# STM32F3x4 register map
File version: 1.8
CPU: CM4 r1p0, little endian, MPU, FPU, 4 interrupt priority bits
Registers are 32-bit, read-write, reset 0x0 unless marked. A register's access mark holds for its fields unless they carry their own. Offsets are from the block's base; [hi:lo] are bit positions; {n}, {i} and the like mark numbered series; 'fields as' and 'values as' point back to an identical list.

## TIM2 — General purpose timer
Base 0x40000000
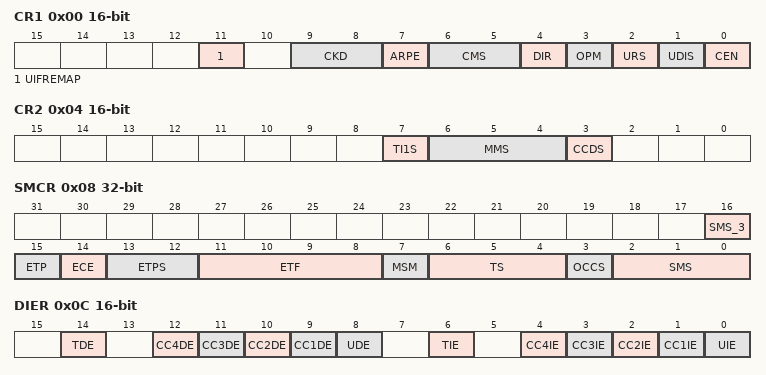
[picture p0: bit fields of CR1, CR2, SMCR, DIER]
0x00 CR1 16-bit — control register 1
  [11] UIFREMAP — UIF status bit remapping
  [9:8] CKD — Clock division
    0=Div1 (t_DTS = t_CK_INT); 1=Div2 (t_DTS = 2 × t_CK_INT); 2=Div4 (t_DTS = 4 × t_CK_INT)
  [7] ARPE — Auto-reload preload enable
    0=Disabled (TIMx_APRR register is not buffered); 1=Enabled (TIMx_APRR register is buffered)
  [6:5] CMS — Center-aligned mode selection
    0=EdgeAligned (The counter counts up or down depending on the direction bit); 1=CenterAligned1 (The counter counts up and down alternatively. Output compare interrupt flags are set only when the counter is counting down.); 2=CenterAligned2 (The counter counts up and down alternatively. Output compare interrupt flags are set only when the counter is counting up.); 3=CenterAligned3 (The counter counts up and down alternatively. Output compare interrupt flags are set both when the counter is counting up or down.)
  [4] DIR — Direction
    0=Up (Counter used as upcounter); 1=Down (Counter used as downcounter)
  [3] OPM — One-pulse mode
    0=Disabled (Counter is not stopped at update event); 1=Enabled (Counter stops counting at the next update event (clearing the CEN bit))
  [2] URS — Update request source
    0=AnyEvent (Any of counter overflow/underflow, setting UG, or update through slave mode, generates an update interrupt or DMA request); 1=CounterOnly (Only counter overflow/underflow generates an update interrupt or DMA request)
  [1] UDIS — Update disable
    0=Enabled (Update event enabled); 1=Disabled (Update event disabled)
  [0] CEN — Counter enable
    0=Disabled (Counter disabled); 1=Enabled (Counter enabled)
0x04 CR2 16-bit — control register 2
  [7] TI1S — TI1 selection
    0=Normal (The TIMx_CH1 pin is connected to TI1 input); 1=XOR (The TIMx_CH1, CH2, CH3 pins are connected to TI1 input)
  [6:4] MMS — Master mode selection
    0=Reset (The UG bit from the TIMx_EGR register is used as trigger output); 1=Enable (The counter enable signal, CNT_EN, is used as trigger output); 2=Update (The update event is selected as trigger output); 3=ComparePulse (The trigger output send a positive pulse when the CC1IF flag it to be set, as soon as a capture or a compare match occurred); {v}=CompareOC{v-3} (OC{v-3}REF signal is used as trigger output) (v=4..7)
  [3] CCDS — Capture/compare DMA selection
    0=OnCompare (CCx DMA request sent when CCx event occurs); 1=OnUpdate (CCx DMA request sent when update event occurs)
0x08 SMCR — slave mode control register
  [16] SMS_3 — Slave mode selection bit3
  [15] ETP — External trigger polarity
    0=NotInverted (ETR is noninverted, active at high level or rising edge); 1=Inverted (ETR is inverted, active at low level or falling edge)
  [14] ECE — External clock enable
    0=Disabled (External clock mode 2 disabled); 1=Enabled (External clock mode 2 enabled. The counter is clocked by any active edge on the ETRF signal.)
  [13:12] ETPS — External trigger prescaler
    0=Div1 (Prescaler OFF); 1=Div2 (ETRP frequency divided by 2); 2=Div4 (ETRP frequency divided by 4); 3=Div8 (ETRP frequency divided by 8)
  [11:8] ETF — External trigger filter
    0=No filter, sampling is done at fDTS; 1=FCK_INT_N2 (fSAMPLING=fCK_INT, N=2); 2=FCK_INT_N4 (fSAMPLING=fCK_INT, N=4); 3=FCK_INT_N8 (fSAMPLING=fCK_INT, N=8); 4=FDTS_Div2_N6 (fSAMPLING=fDTS/2, N=6); 5=FDTS_Div2_N8 (fSAMPLING=fDTS/2, N=8); 6=FDTS_Div4_N6 (fSAMPLING=fDTS/4, N=6); 7=FDTS_Div4_N8 (fSAMPLING=fDTS/4, N=8); 8=FDTS_Div8_N6 (fSAMPLING=fDTS/8, N=6); 9=FDTS_Div8_N8 (fSAMPLING=fDTS/8, N=8); 10=FDTS_Div16_N5 (fSAMPLING=fDTS/16, N=5); 11=FDTS_Div16_N6 (fSAMPLING=fDTS/16, N=6); 12=FDTS_Div16_N8 (fSAMPLING=fDTS/16, N=8); 13=FDTS_Div32_N5 (fSAMPLING=fDTS/32, N=5); 14=FDTS_Div32_N6 (fSAMPLING=fDTS/32, N=6); 15=FDTS_Div32_N8 (fSAMPLING=fDTS/32, N=8)
  [7] MSM — Master/Slave mode
    0=NoSync (No action); 1=Sync (The effect of an event on the trigger input (TRGI) is delayed to allow a perfect synchronization between the current timer and its slaves (through TRGO). It is useful if we want to synchronize several timers on a single external event.)
  [6:4] TS — Trigger selection
    0=ITR0 (Internal Trigger 0 (ITR0)); 1=ITR1 (Internal Trigger 1 (ITR1)); 2=ITR2 (Internal Trigger 2 (ITR2)); 4=TI1F_ED (TI1 Edge Detector (TI1F_ED)); 5=TI1FP1 (Filtered Timer Input 1 (TI1FP1)); 6=TI2FP2 (Filtered Timer Input 2 (TI2FP2)); 7=ETRF (External Trigger input (ETRF))
  [3] OCCS — OCREF clear selection
  [2:0] SMS — Slave mode selection
    0=Disabled (Slave mode disabled - if CEN = ‘1 then the prescaler is clocked directly by the internal clock.); 1=Encoder mode 1 - Counter counts up/down on TI2FP1 edge depending on TI1FP2 level; 2=Encoder mode 2 - Counter counts up/down on TI1FP2 edge depending on TI2FP1 level; 3=Encoder mode 3 - Counter counts up/down on both TI1FP1 and TI2FP2 edges depending on the level of the other input; 4=Reset Mode - Rising edge of the selected trigger input (TRGI) reinitializes the counter and generates an update of the registers; 5=Gated Mode - The counter clock is enabled when the trigger input (TRGI) is high. The counter stops (but is not reset) as soon as the trigger becomes low. Both start and stop of the counter are controlled.; 6=Trigger Mode - The counter starts at a rising edge of the trigger TRGI (but it is not reset). Only the start of the counter is controlled.; 7=Ext_Clock_Mode (External Clock Mode 1 - Rising edges of the selected trigger (TRGI) clock the counter.)
0x0C DIER 16-bit — DMA/Interrupt enable register
  [14] TDE — Trigger DMA request enable
    0=Disabled (Trigger DMA request disabled); 1=Enabled (Trigger DMA request enabled)
  [n+8] CC{n}DE (n=1..4) — Capture/Compare {n} DMA request enable
    0=Disabled (CCx DMA request disabled); 1=Enabled (CCx DMA request enabled)
  [8] UDE — Update DMA request enable
    0=Disabled (Update DMA request disabled); 1=Enabled (Update DMA request enabled)
  [6] TIE — Trigger interrupt enable
    0=Disabled (Trigger interrupt disabled); 1=Enabled (Trigger interrupt enabled)
  [n] CC{n}IE (n=1..4) — Capture/Compare {n} interrupt enable
    0=Disabled (CCx interrupt disabled); 1=Enabled (CCx interrupt enabled)
  [0] UIE — Update interrupt enable
    0=Disabled (Update interrupt disabled); 1=Enabled (Update interrupt enabled)
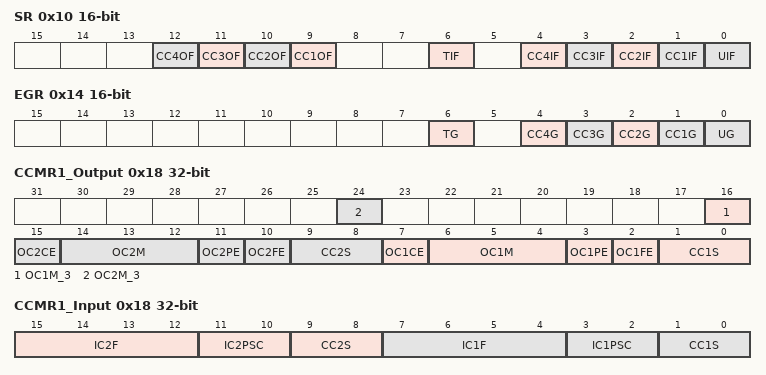
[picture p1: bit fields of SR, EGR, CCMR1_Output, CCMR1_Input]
0x10 SR 16-bit — status register
  [n+8] CC{n}OF (n=1..4) write-0-clears — Capture/Compare {n} overcapture flag
    on read: 0=No overcapture has been detected; 1=Overcapture (The counter value has been captured in TIMx_CCRx register while CCxIF flag was already set) | on write: 0=Clear flag
  [6] TIF write-0-clears — Trigger interrupt flag
    on read: 0=No trigger event occurred; 1=Trigger interrupt pending | on write: 0=Clear flag
  [n] CC{n}IF (n=1..4) write-0-clears — Capture/compare {n} interrupt flag
    on read: 0=NoMatch (No campture/compare has been detected); 1=Match (If CC1 is an output: The content of the counter TIMx_CNT matches the content of the TIMx_CCR1 register. If CC1 is an input: The counter value has been captured in TIMx_CCR1 register.) | on write: 0=Clear flag
  [0] UIF write-0-clears — Update interrupt flag
    on read: 0=NoUpdateOccurred; 1=UpdatePending (Update interrupt pending) | on write: 0=Clear flag
0x14 EGR 16-bit wo — event generation register
  [6] TG — Trigger generation
    1=Trigger (The TIF flag is set in TIMx_SR register. Related interrupt or DMA transfer can occur if enabled.)
  [n] CC{n}G (n=1..4) — Capture/compare {n} generation
    1=Trigger (If CC1 is an output: CC1IF flag is set, Corresponding interrupt or DMA request is sent if enabled. If CC1 is an input: The current value of the counter is captured in TIMx_CCR1 register.)
  [0] UG — Update generation
    1=Update (Re-initializes the timer counter and generates an update of the registers.)
0x18 CCMR1_Output — capture/compare mode register 1 (output mode)
  [8n+8] OC{n}M_3 (n=1..2) — Output compare {n} mode, bit 3
    0=Normal output compare mode (modes 0-7); 1=Extended output compare mode (modes 7-15)
  [8n-1] OC{n}CE (n=1..2) — Output compare {n} clear enable
    0=Disabled (OCxRef is not affected by the ETRF signal); 1=Enabled (OCxRef is cleared as soon as a High level is detected on ETRF signal)
  [8n-2:8n-4] OC{n}M (n=1..2) — Output compare {n} mode
    0=Frozen (The comparison between the output compare register TIMx_CCRy and the counter TIMx_CNT has no effect on the outputs / OpmMode1: Retriggerable OPM mode 1 - In up-counting mode, the channel is active until a trigger event is detected (on TRGI signal). In down-counting mode, the channel is inactive); 1=ActiveOnMatch (Set channel to active level on match. OCyREF signal is forced high when the counter matches the capture/compare register / OpmMode2: Inversely to OpmMode1); 2=InactiveOnMatch (Set channel to inactive level on match. OCyREF signal is forced low when the counter matches the capture/compare register / Reserved); 3=Toggle (OCyREF toggles when TIMx_CNT=TIMx_CCRy / Reserved); 4=ForceInactive (OCyREF is forced low / CombinedPwmMode1: OCyREF has the same behavior as in PWM mode 1. OCyREFC is the logical OR between OC1REF and OC2REF); 5=ForceActive (OCyREF is forced high / CombinedPwmMode2: OCyREF has the same behavior as in PWM mode 2. OCyREFC is the logical AND between OC1REF and OC2REF); 6=PwmMode1 (In upcounting, channel is active as long as TIMx_CNT<TIMx_CCRy else inactive. In downcounting, channel is inactive as long as TIMx_CNT>TIMx_CCRy else active / AsymmetricPwmMode1: OCyREF has the same behavior as in PWM mode 1. OCyREFC outputs OC1REF when the counter is counting up, OC2REF when it is counting down); 7=PwmMode2 (Inversely to PwmMode1 / AsymmetricPwmMode2: Inversely to AsymmetricPwmMode1)
  [8n-5] OC{n}PE (n=1..2) — Output compare {n} preload enable
    0=Disabled (Preload register on CCRx disabled. New values written to CCRx are taken into account immediately); 1=Enabled (Preload register on CCRx enabled. Preload value is loaded into active register on each update event)
  [8n-6] OC{n}FE (n=1..2) — Output compare {n} fast enable
    0=Disabled (Fast output disabled); 1=Enabled (Fast output enabled)
  [8n-7:8n-8] CC{n}S (n=1..2) — Capture/Compare {n} selection
    0=Output (CCx channel is configured as output)
0x18 CCMR1_Input (alternate view of CCMR1_Output) — capture/compare mode register 1 (input mode)
  [9:8] CC2S — Capture/compare 2 selection
    1=TI2 (CC2 channel is configured as input, IC2 is mapped on TI2); 2=TI1 (CC2 channel is configured as input, IC2 is mapped on TI1); 3=TRC (CC2 channel is configured as input, IC2 is mapped on TRC)
  [8n-1:8n-4] IC{n}F (n=1..2) — Input capture {n} filter
    values as SMCR.ETF
  [8n-5:8n-6] IC{n}PSC (n=1..2) — Input capture {n} prescaler
    0=No prescaler, capture is done each time an edge is detected on the capture input; 1=TwoEvents (Capture is done once every 2 events); 2=FourEvents (Capture is done once every 4 events); 3=EightEvents (Capture is done once every 8 events)
  [1:0] CC1S — Capture/Compare 1 selection
    1=TI1 (CC1 channel is configured as input, IC1 is mapped on TI1); 2=TI2 (CC1 channel is configured as input, IC1 is mapped on TI2); 3=TRC (CC1 channel is configured as input, IC1 is mapped on TRC)
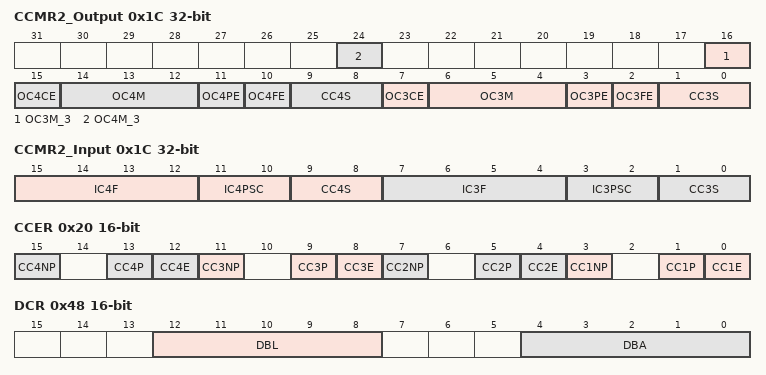
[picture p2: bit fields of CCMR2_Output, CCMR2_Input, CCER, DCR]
0x1C CCMR2_Output — capture/compare mode register 2 (output mode)
  [8n-8] OC{n}M_3 (n=3..4) — Output compare {n} mode, bit 3
    values as CCMR1_Output.OC1M_3
  [8n-17] OC{n}CE (n=3..4) — Output compare {n} clear enable
    values as CCMR1_Output.OC1CE
  [8n-18:8n-20] OC{n}M (n=3..4) — Output compare {n} mode
    values as CCMR1_Output.OC1M
  [8n-21] OC{n}PE (n=3..4) — Output compare {n} preload enable
    values as CCMR1_Output.OC1PE
  [8n-22] OC{n}FE (n=3..4) — Output compare {n} fast enable
    values as CCMR1_Output.OC1FE
  [8n-23:8n-24] CC{n}S (n=3..4) — Capture/Compare {n} selection
    0=Output (CCx channel is configured as output)
0x1C CCMR2_Input (alternate view of CCMR2_Output) — capture/compare mode register 2 (input mode)
  [9:8] CC4S — Capture/Compare 4 selection
    1=TI4 (CC4 channel is configured as input, IC4 is mapped on TI4); 2=TI3 (CC4 channel is configured as input, IC4 is mapped on TI3); 3=TRC (CC4 channel is configured as input, IC4 is mapped on TRC)
  [8n-17:8n-20] IC{n}F (n=3..4) — Input capture {n} filter
    values as SMCR.ETF
  [8n-21:8n-22] IC{n}PSC (n=3..4) — Input capture {n} prescaler
    values as CCMR1_Input.IC1PSC
  [1:0] CC3S — Capture/Compare 3 selection
    1=TI3 (CC3 channel is configured as input, IC3 is mapped on TI3); 2=TI4 (CC3 channel is configured as input, IC3 is mapped on TI4); 3=TRC (CC3 channel is configured as input, IC3 is mapped on TRC)
0x20 CCER 16-bit — capture/compare enable register
  [4n-1] CC{n}NP (n=1..4) — Capture/Compare {n} output Polarity
  [4n-3] CC{n}P (n=1..4) — Capture/Compare {n} output Polarity
    0=RisingEdge (Noninverted/rising edge); 1=FallingEdge (Inverted/falling edge)
  [4n-4] CC{n}E (n=1..4) — Capture/Compare {n} output enable
    0=Disabled (Capture disabled); 1=Enabled (Capture enabled)
0x24 CNT — counter
  [31:0] CNT — Low counter value
0x24 CNT32 (alternate view of CNT) — 32-bit counter register
  [31:0] CNT — counter value
0x28 PSC 16-bit — prescaler
  [15:0] PSC — Prescaler value
0x2C ARR — auto-reload register
  [31:0] ARR — Low Auto-reload value
{0x30+4i} CCR{i} (i=1..4) — capture/compare register
  [31:0] CCR — Capture/Compare value
0x48 DCR 16-bit — DMA control register
  [12:8] DBL range 0..18 — DMA burst length
  [4:0] DBA — DMA base address
0x4C DMAR 16-bit — DMA address for full transfer
  [15:0] DMAB — DMA register for burst accesses

## TIM3 — General purpose timer
Base 0x40000400
Registers as TIM2, without CNT32; these are added or differ:
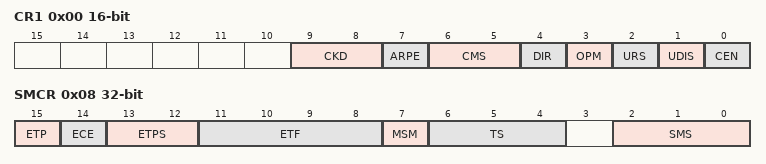
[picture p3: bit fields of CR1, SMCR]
0x00 CR1 16-bit — control register 1
  [9:8] CKD — Clock division
    0=Div1 (t_DTS = t_CK_INT); 1=Div2 (t_DTS = 2 × t_CK_INT); 2=Div4 (t_DTS = 4 × t_CK_INT)
  [7] ARPE — Auto-reload preload enable
    0=Disabled (TIMx_APRR register is not buffered); 1=Enabled (TIMx_APRR register is buffered)
  [6:5] CMS — Center-aligned mode selection
    values as TIM2.CR1.CMS
  [4] DIR — Direction
    0=Up (Counter used as upcounter); 1=Down (Counter used as downcounter)
  [3] OPM — One-pulse mode
    0=Disabled (Counter is not stopped at update event); 1=Enabled (Counter stops counting at the next update event (clearing the CEN bit))
  [2] URS — Update request source
    values as TIM2.CR1.URS
  [1] UDIS — Update disable
    0=Enabled (Update event enabled); 1=Disabled (Update event disabled)
  [0] CEN — Counter enable
    0=Disabled (Counter disabled); 1=Enabled (Counter enabled)
0x08 SMCR — slave mode control register
  [15] ETP — External trigger polarity
    0=NotInverted (ETR is noninverted, active at high level or rising edge); 1=Inverted (ETR is inverted, active at low level or falling edge)
  [14] ECE — External clock enable
    0=Disabled (External clock mode 2 disabled); 1=Enabled (External clock mode 2 enabled. The counter is clocked by any active edge on the ETRF signal.)
  [13:12] ETPS — External trigger prescaler
    0=Div1 (Prescaler OFF); 1=Div2 (ETRP frequency divided by 2); 2=Div4 (ETRP frequency divided by 4); 3=Div8 (ETRP frequency divided by 8)
  [11:8] ETF — External trigger filter
    values as TIM2.SMCR.ETF
  [7] MSM — Master/Slave mode
    values as TIM2.SMCR.MSM
  [6:4] TS — Trigger selection
    values as TIM2.SMCR.TS
  [2:0] SMS — Slave mode selection
    values as TIM2.SMCR.SMS
0x24 CNT — counter
  [15:0] CNT — counter value
0x24 CNT16 16-bit (alternate view of CNT) — 16-bit counter register
  [15:0] CNT — counter value
0x2C ARR 16-bit reset 0xFFFF — auto-reload register
  [15:0] ARR — Auto-reload value
{0x30+4i} CCR{i} (i=1..4) 16-bit — capture/compare register
  [15:0] CCR — Capture/Compare value
